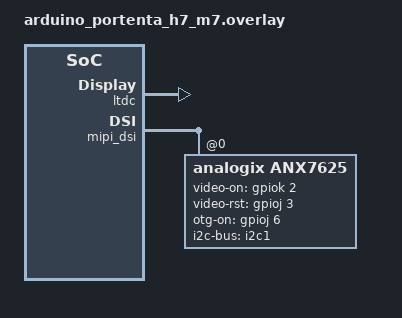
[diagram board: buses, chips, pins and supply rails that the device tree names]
/*
 * Copyright (c) 2025 Arduino SA
 *
 * SPDX-License-Identifier: Apache-2.0
 *
 * Portenta H7 on-board USB-C video output via the ANX7625 MIPI-DSI -> DP/HDMI
 * bridge. Mutually exclusive with arduino_giga_display_shield (both drive the
 * LTDC + MIPI-DSI host, so only one may be selected at a time).
 */

#include <zephyr/dt-bindings/display/panel.h>
#include <zephyr/dt-bindings/gpio/gpio.h>

/ {
	chosen {
		zephyr,display = &ltdc;
		zephyr,mipi-dsi = &mipi_dsi;
	};
};

/*
 * PLL3 calculation for 1024x768@60Hz (57.8 MHz pixel clock)
 * Portenta H7 uses 25 MHz HSE crystal
 * VCO input = HSE / div-m = 25 MHz / 25 = 1 MHz
 * VCO output = VCO input x mul-n = 1 MHz x 289 = 289 MHz
 * Pixel clock = VCO output / div-r = 289 MHz / 5 = 57.8 MHz
 */
&pll3 {
	status = "okay";
	clocks = <&clk_hse>;
	div-m = <25>;   /* HSE_VALUE/1MHz: 25MHz/25 = 1 MHz VCO input */
	mul-n = <289>;  /* pixelclock/200kHz: 57800/200 = 289 */
	div-p = <2>;
	div-q = <7>;
	div-r = <5>;    /* 1000/200kHz = 5 -> 289MHz/5 = 57.8 MHz */
};

&ltdc {
	status = "okay";
	ext-sdram = <&sdram1>;
	width = <1024>;
	height = <768>;
	def-back-color-red = <0>;
	def-back-color-green = <0>;
	def-back-color-blue = <0>;
	pixel-format = <PANEL_PIXEL_FORMAT_RGB_888>;

	display-timings {
		compatible = "zephyr,panel-timing";
		hsync-active = <0>;
		vsync-active = <0>;
		de-active = <0>;
		pixelclk-active = <0>;
		hsync-len = <68>;
		hfront-porch = <24>;
		hback-porch = <80>;
		vsync-len = <6>;
		vfront-porch = <3>;
		vback-porch = <29>;
	};
};

&mipi_dsi {
	status = "okay";

	pll-ndiv = <40>;
	pll-idf = <2>;
	pll-odf = <0>;

	de-active-high;
	bta-ack-disable;  /* ANX7625 bridge doesn't respond to BTA requests */
	largest-packet-size = <16>;

	phy-timings = <35 35 35 35 0 10>;

	/*
	 * This binding allows adding child node with with data-lanes property
	 * as required by STM32 MIPI-DSI driver.
	 */
	anx7625: anx7625@0 {
		status = "okay";
		compatible = "analogix,anx7625";
		reg = <0>;  /* Virtual channel 0 */
		pixel-format = <0>;  /* Not used */
		data-lanes = <2>;  /* 2 data lanes */
		i2c-bus = <&i2c1>;
		video-on-gpios = <&gpiok 2 GPIO_ACTIVE_HIGH>;
		video-rst-gpios = <&gpioj 3 GPIO_ACTIVE_HIGH>;
		otg-on-gpios = <&gpioj 6 (GPIO_ACTIVE_HIGH | GPIO_PULL_UP)>;
	};
};
